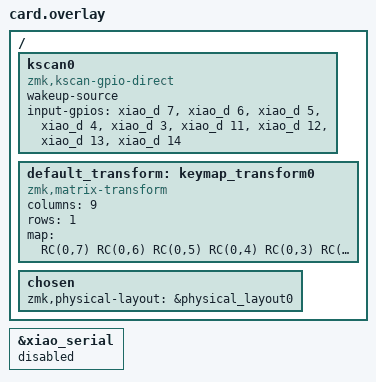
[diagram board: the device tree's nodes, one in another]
#include <dt-bindings/zmk/matrix_transform.h> // Put this with the other includes at the top of your overlay
#include "card-layouts.dtsi"

/ {
    kscan0: kscan0 {
        compatible = "zmk,kscan-gpio-direct";
        wakeup-source;

        input-gpios
            = <&xiao_d 7 (GPIO_ACTIVE_HIGH | GPIO_PULL_DOWN)>,
			<&xiao_d 6 (GPIO_ACTIVE_HIGH | GPIO_PULL_DOWN)>,
			<&xiao_d 5 (GPIO_ACTIVE_HIGH | GPIO_PULL_DOWN)>,
			<&xiao_d 4 (GPIO_ACTIVE_HIGH | GPIO_PULL_DOWN)>,
			<&xiao_d 3 (GPIO_ACTIVE_HIGH | GPIO_PULL_DOWN)>,
			<&xiao_d 11 (GPIO_ACTIVE_HIGH | GPIO_PULL_DOWN)>,
			<&xiao_d 12 (GPIO_ACTIVE_HIGH | GPIO_PULL_DOWN)>,
			<&xiao_d 13 (GPIO_ACTIVE_HIGH | GPIO_PULL_DOWN)>,
			<&xiao_d 14 (GPIO_ACTIVE_HIGH | GPIO_PULL_DOWN)>
			;

    };
};

&xiao_serial { status = "disabled"; };

/ {
    default_transform: keymap_transform0 {
        compatible = "zmk,matrix-transform";
        columns = <9>; // Length of the "col-gpios" array
        rows = <1>; // Length of the "row-gpios" array
        map = <
        
        RC(0,7) // Green
        RC(0,6) // Red
        RC(0,5) // Yellow
        RC(0,4) // Blue
        RC(0,3) // Orange
        RC(0,11) // DOWN
        RC(0,12) // C
        RC(0,13) // L2
        RC(0,14) // LEFT
        
        >;
    };
};

/ {
    chosen {
        zmk,physical-layout = &physical_layout0;
        // zmk,matrix-transform = &default_transform;
        // Other chosen items
    };
};
